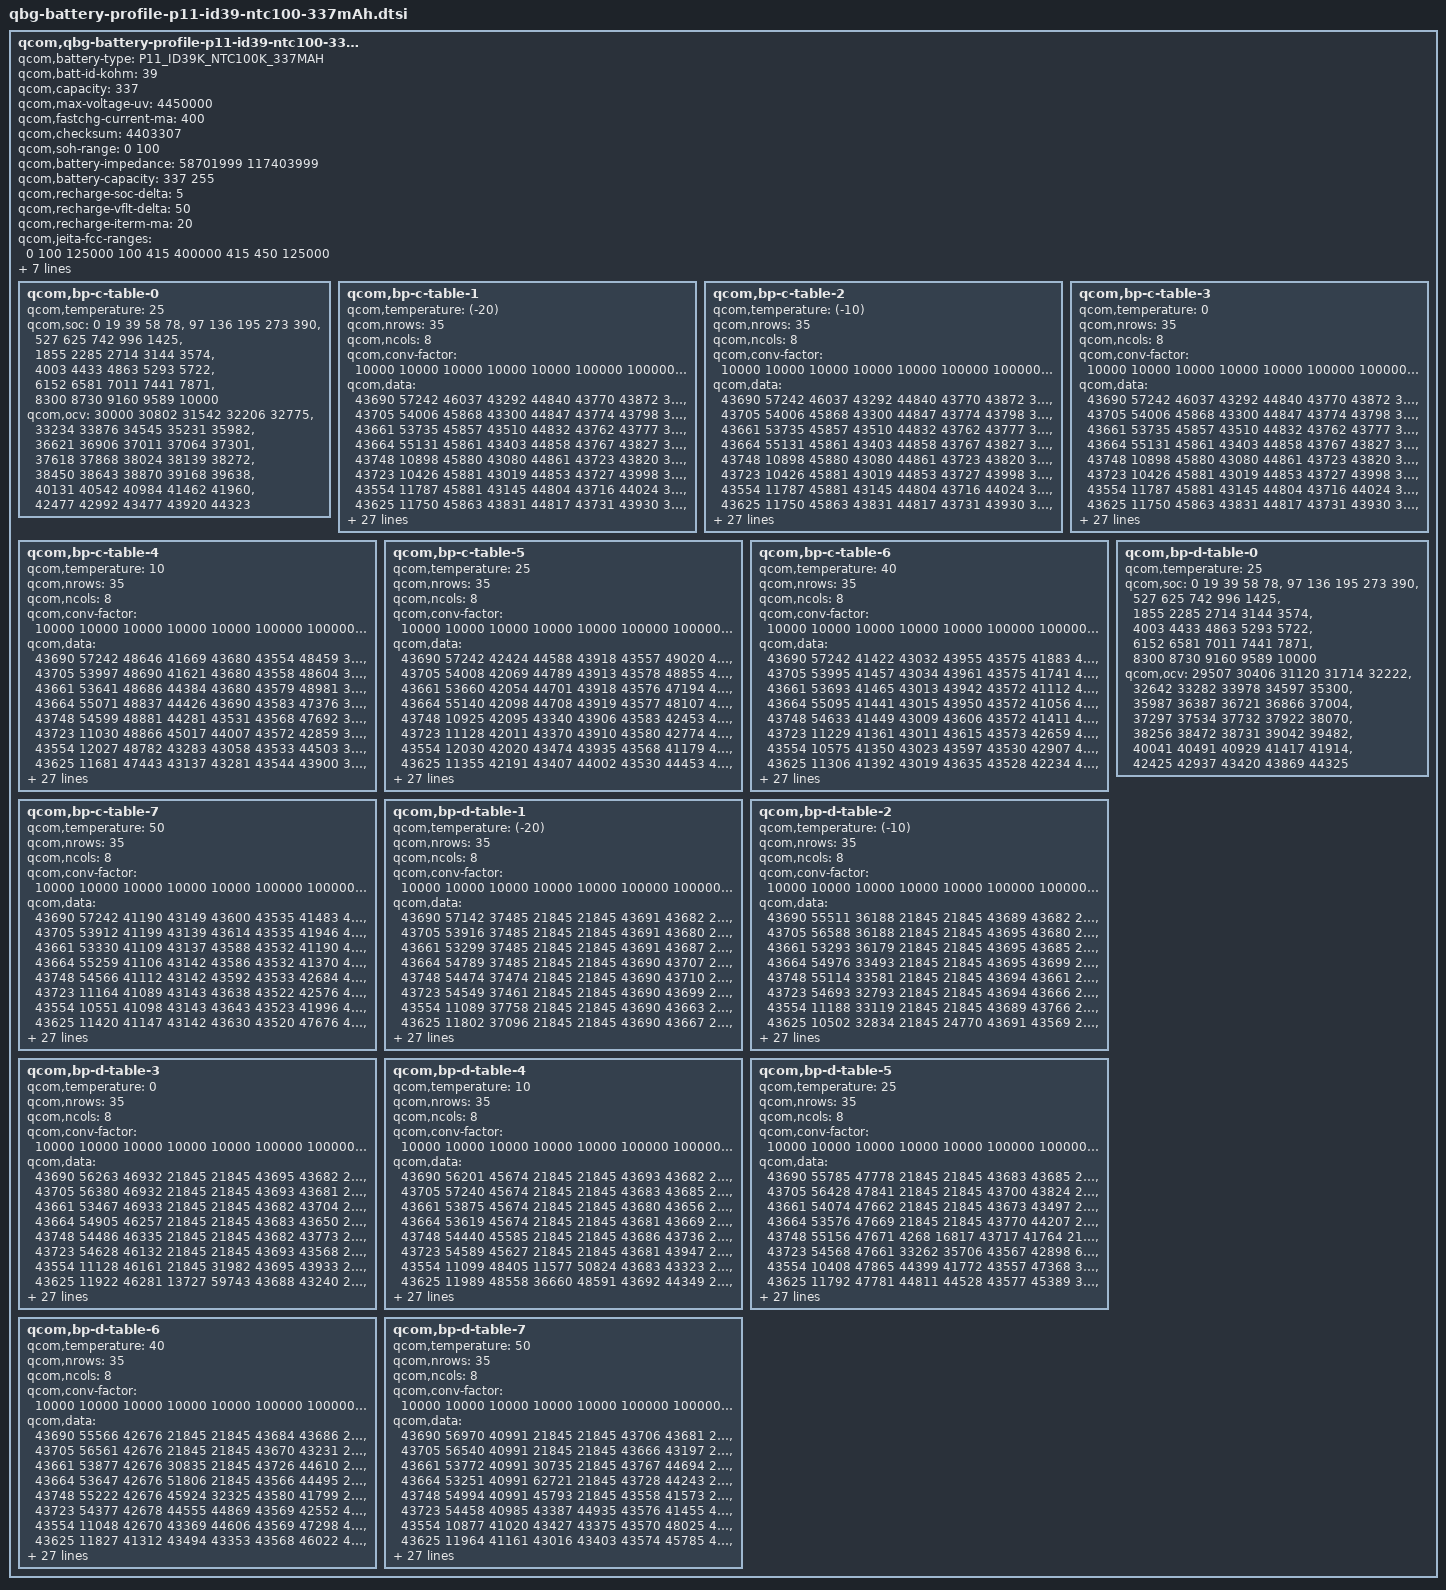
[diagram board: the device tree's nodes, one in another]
// SPDX-License-Identifier: GPL-2.0

/*QBG Profiling Rev. 2.7*/

qcom,qbg-battery-profile-p11-id39-ntc100-337mAh {
	qcom,battery-type = "P11_ID39K_NTC100K_337MAH";
	qcom,batt-id-kohm = <39>;
	qcom,capacity = <337>;
	qcom,max-voltage-uv = <4450000>;
	qcom,fastchg-current-ma = <400>;
	/*@5, 0.005V, 4% */
	qcom,checksum = <4403307>; /*@5, 0.005V, 4% */
	qcom,soh-range = <0 100>;
	/* Nominal_Impedance in 10nohm @ SOC 50% 25C* 0:fresh cell, 1: aged cell */
	qcom,battery-impedance = <58701999 117403999>;
	/* Nominal_Capacity in mAh. 0: fresh cell, 1:aged cell */
	/* 100% 80% */
	qcom,battery-capacity = <337 255>;
	/* SOC delta (in percent) dropped from EOC SOC to enable recharge */
	qcom,recharge-soc-delta =<5>;
	/* vfloat delta (in mV) dropped from regular vfloat in recharge */
	qcom,recharge-vflt-delta =<50>;
	/* termination current (in mA) in recharge */
	qcom,recharge-iterm-ma = <20>;

	/* LowTemp HighTemp CharingCurrent (uA) */
	qcom,jeita-fcc-ranges = <0  100 125000
				100 415 400000
				415 450 125000>;

	qcom,jeita-fv-ranges = <0   100 4450000
				100 415 4450000
				415 450 4450000>;

	/* COOL = 10 DegC, WARM = 41.5 DegC */
	qcom,jeita-soft-thresholds = <0x2b8a 0x1491>;
	/* COLD = 0 DegC, HOT = 45 DegC */
	qcom,jeita-hard-thresholds = <0x3257 0x128c>;
	/* COOL = 12 DegC, WARM = 39.5 DegC*/
	qcom,jeita-soft-hys-thresholds = <0x2a0b 0x15ca>;
	qcom,jeita-soft-fcc-ua = <125000 125000>;
	qcom,jeita-soft-fv-uv = <4450000 4450000>;

	qcom,bp-c-table-0 {
		qcom,temperature = <25>;
		qcom,soc = <    0    19    39    58    78>,
			<   97   136   195   273   390>,
			<  527   625   742   996  1425>,
			< 1855  2285  2714  3144  3574>,
			< 4003  4433  4863  5293  5722>,
			< 6152  6581  7011  7441  7871>,
			< 8300  8730  9160  9589 10000>;
		qcom,ocv = <30000 30802 31542 32206 32775>,
			<33234 33876 34545 35231 35982>,
			<36621 36906 37011 37064 37301>,
			<37618 37868 38024 38139 38272>,
			<38450 38643 38870 39168 39638>,
			<40131 40542 40984 41462 41960>,
			<42477 42992 43477 43920 44323>;
	};
	qcom,bp-c-table-1 {
		qcom,temperature = <(-20)>;
		qcom,nrows = <35>;
		qcom,ncols = <8>;
		qcom,conv-factor = <10000 10000 10000 10000 10000 100000 100000 10000>;
		qcom,data = <43690 57242 46037 43292 44840 43770 43872 39629>,
			<43705 54006 45868 43300 44847 43774 43798 34136>,
			<43661 53735 45857 43510 44832 43762 43777 34263>,
			<43664 55131 45861 43403 44858 43767 43827 34211>,
			<43748 10898 45880 43080 44861 43723 43820 33853>,
			<43723 10426 45881 43019 44853 43727 43998 33920>,
			<43554 11787 45881 43145 44804 43716 44024 34807>,
			<43625 11750 45863 43831 44817 43731 43930 34507>,
			<43963  8367 45982 43982 44803 43565 43904 33235>,
			<43820  9814 46011 43815 45006 43571 44005 32883>,
			<43173  9680 45632 43840 44669 43524 43830 32992>,
			<43227 14848 45682 43907 45024 43545 43932 33558>,
			<43084 15264 45685 43935 45017 43545 43909 33543>,
			<43342 15345 45646 43208 44758 43545 43845 33565>,
			<44859 14480 45662 41496 43228 43570 47692 34770>,
			<44437 14807 45641 41097 43453 43559 47566 33806>,
			<41543 16080 45617 41076 43481 43555 47505 33865>,
			<41008 16265 45760 41421 43278 43564 47877 33874>,
			<42722 16337 45604 41321 43347 43566 47710 34256>,
			<42844 16201 45794 41302 44777 43560 42430 34175>,
			<42249 15606 45811 42640 44551 43733 42174 39626>,
			<48123 15478 45799 42548 44943 43732 42381 39863>,
			<47189 15833 45720 42935 45004 43733 48768 39702>,
			<48647 13018 45697 42981 45036 43562 48413 39705>,
			<48368 12324 45792 42504 43266 43733 42519 34275>,
			<45730 12626 45643 42762 44798 43743 41214 39890>,
			<45855 14141 45640 42044 44606 43716 41552 39387>,
			<45513 13719 46012 42466 44981 43714 44485 40756>,
			<47035  2630 45867 42313 44186 43727 44887 37529>,
			<46101  2067 45936 47836 44326 43726 44969 37268>,
			<35526  3633 45070 47736 41735 43726 44721 38285>,
			<34992  3130 45181 47689 42924 43725 43492 60950>,
			<35170   546 45442 47817 47337 43719 43010 59125>,
			<36831   247 45328 42402 45363 43717 43188 62183>,
			<36282  1713 46795 41711 45227 43618 43921 65312>;
	};
	qcom,bp-c-table-2 {
		qcom,temperature = <(-10)>;
		qcom,nrows = <35>;
		qcom,ncols = <8>;
		qcom,conv-factor = <10000 10000 10000 10000 10000 100000 100000 10000>;
		qcom,data = <43690 57242 46037 43292 44840 43770 43872 39629>,
			<43705 54006 45868 43300 44847 43774 43798 34136>,
			<43661 53735 45857 43510 44832 43762 43777 34263>,
			<43664 55131 45861 43403 44858 43767 43827 34211>,
			<43748 10898 45880 43080 44861 43723 43820 33853>,
			<43723 10426 45881 43019 44853 43727 43998 33920>,
			<43554 11787 45881 43145 44804 43716 44024 34807>,
			<43625 11750 45863 43831 44817 43731 43930 34507>,
			<43963  8367 45982 43982 44803 43565 43904 33235>,
			<43820  9814 46011 43815 45006 43571 44005 32883>,
			<43173  9680 45632 43840 44669 43524 43830 32992>,
			<43227 14848 45682 43907 45024 43545 43932 33558>,
			<43084 15264 45685 43935 45017 43545 43909 33543>,
			<43342 15345 45646 43208 44758 43545 43845 33565>,
			<44859 14480 45662 41496 43228 43570 47692 34770>,
			<44437 14807 45641 41097 43453 43559 47566 33806>,
			<41543 16080 45617 41076 43481 43555 47505 33865>,
			<41008 16265 45760 41421 43278 43564 47877 33874>,
			<42722 16337 45604 41321 43347 43566 47710 34256>,
			<42844 16201 45794 41302 44777 43560 42430 34175>,
			<42249 15606 45811 42640 44551 43733 42174 39626>,
			<48123 15478 45799 42548 44943 43732 42381 39863>,
			<47189 15833 45720 42935 45004 43733 48768 39702>,
			<48647 13018 45697 42981 45036 43562 48413 39705>,
			<48368 12324 45792 42504 43266 43733 42519 34275>,
			<45730 12626 45643 42762 44798 43743 41214 39890>,
			<45855 14141 45640 42044 44606 43716 41552 39387>,
			<45513 13719 46012 42466 44981 43714 44485 40756>,
			<47035  2630 45867 42313 44186 43727 44887 37529>,
			<46101  2067 45936 47836 44326 43726 44969 37268>,
			<35526  3633 45070 47736 41735 43726 44721 38285>,
			<34992  3130 45181 47689 42924 43725 43492 60950>,
			<35170   546 45442 47817 47337 43719 43010 59125>,
			<36831   247 45328 42402 45363 43717 43188 62183>,
			<36282  1713 46795 41711 45227 43618 43921 65312>;
	};
	qcom,bp-c-table-3 {
		qcom,temperature = <0>;
		qcom,nrows = <35>;
		qcom,ncols = <8>;
		qcom,conv-factor = <10000 10000 10000 10000 10000 100000 100000 10000>;
		qcom,data = <43690 57242 46037 43292 44840 43770 43872 39629>,
			<43705 54006 45868 43300 44847 43774 43798 34136>,
			<43661 53735 45857 43510 44832 43762 43777 34263>,
			<43664 55131 45861 43403 44858 43767 43827 34211>,
			<43748 10898 45880 43080 44861 43723 43820 33853>,
			<43723 10426 45881 43019 44853 43727 43998 33920>,
			<43554 11787 45881 43145 44804 43716 44024 34807>,
			<43625 11750 45863 43831 44817 43731 43930 34507>,
			<43963  8367 45982 43982 44803 43565 43904 33235>,
			<43820  9814 46011 43815 45006 43571 44005 32883>,
			<43173  9680 45632 43840 44669 43524 43830 32992>,
			<43227 14848 45682 43907 45024 43545 43932 33558>,
			<43084 15264 45685 43935 45017 43545 43909 33543>,
			<43342 15345 45646 43208 44758 43545 43845 33565>,
			<44859 14480 45662 41496 43228 43570 47692 34770>,
			<44437 14807 45641 41097 43453 43559 47566 33806>,
			<41543 16080 45617 41076 43481 43555 47505 33865>,
			<41008 16265 45760 41421 43278 43564 47877 33874>,
			<42722 16337 45604 41321 43347 43566 47710 34256>,
			<42844 16201 45794 41302 44777 43560 42430 34175>,
			<42249 15606 45811 42640 44551 43733 42174 39626>,
			<48123 15478 45799 42548 44943 43732 42381 39863>,
			<47189 15833 45720 42935 45004 43733 48768 39702>,
			<48647 13018 45697 42981 45036 43562 48413 39705>,
			<48368 12324 45792 42504 43266 43733 42519 34275>,
			<45730 12626 45643 42762 44798 43743 41214 39890>,
			<45855 14141 45640 42044 44606 43716 41552 39387>,
			<45513 13719 46012 42466 44981 43714 44485 40756>,
			<47035  2630 45867 42313 44186 43727 44887 37529>,
			<46101  2067 45936 47836 44326 43726 44969 37268>,
			<35526  3633 45070 47736 41735 43726 44721 38285>,
			<34992  3130 45181 47689 42924 43725 43492 60950>,
			<35170   546 45442 47817 47337 43719 43010 59125>,
			<36831   247 45328 42402 45363 43717 43188 62183>,
			<36282  1713 46795 41711 45227 43618 43921 65312>;
	};
	qcom,bp-c-table-4 {
		qcom,temperature = <10>;
		qcom,nrows = <35>;
		qcom,ncols = <8>;
		qcom,conv-factor = <10000 10000 10000 10000 10000 100000 100000 10000>;
		qcom,data = <43690 57242 48646 41669 43680 43554 48459 35142>,
			<43705 53997 48690 41621 43680 43558 48604 35113>,
			<43661 53641 48686 44384 43680 43579 48981 35263>,
			<43664 55071 48837 44426 43690 43583 47376 34830>,
			<43748 54599 48881 44281 43531 43568 47692 34969>,
			<43723 11030 48866 45017 44007 43572 42859 35694>,
			<43554 12027 48782 43283 43058 43533 44503 35420>,
			<43625 11681 47443 43137 43281 43544 43900 35493>,
			<43963  9071 47486 43167 43318 43543 43890 46557>,
			<43820  9749 47434 43236 43508 43618 43198 46146>,
			<43173  9707 47398 43121 43010 43625 43416 46284>,
			<43227 15043 47557 43403 43164 43542 44691 46935>,
			<43084 14951 47569 43285 43838 43540 41654 46926>,
			<43342 15266 47556 44745 43983 43624 42071 46261>,
			<44859 15197 47564 44042 43253 43580 42223 35401>,
			<44437 14740 47517 44533 43439 43559 42407 35591>,
			<41543 16023 47524 44415 43405 43555 42317 35695>,
			<41008 15997 47231 41628 43394 43565 48041 35691>,
			<42722 16281 47108 41671 43492 43565 47708 35705>,
			<42844 16140 47160 41504 43483 43565 42123 35663>,
			<42249 15508 47137 41703 44716 43566 41773 34958>,
			<48123 15439 47312 41628 44572 43563 41579 34861>,
			<47189 15671 47345 41671 44976 43732 41167 35248>,
			<48647 12863 47328 41919 44609 43562 47207 35218>,
			<48368 12422 47341 41963 43341 43561 48247 35038>,
			<45730 14023 47249 41619 43455 43562 44395 35544>,
			<45855 14173 47256 41892 43074 43734 41097 35765>,
			<45513 13620 47239 41971 43449 43730 41533 35599>,
			<47035  3017 47339 41119 43264 43717 44107 35302>,
			<46101  2537 47145 41390 44547 43713 44833 36637>,
			<35526  3997 47174 41422 44213 43718 44763 33489>,
			<34992  3475 47604 41256 41672 43717 43321 34470>,
			<35170   903 47480 41431 41336 43741 43448 39850>,
			<36831    91 48893 41010 47271 43562 43052 37462>,
			<36282  1547 48903 44635 48541 43924 43911 37362>;
	};
	qcom,bp-c-table-5 {
		qcom,temperature = <25>;
		qcom,nrows = <35>;
		qcom,ncols = <8>;
		qcom,conv-factor = <10000 10000 10000 10000 10000 100000 100000 10000>;
		qcom,data = <43690 57242 42424 44588 43918 43557 49020 48210>,
			<43705 54008 42069 44789 43913 43578 48855 48148>,
			<43661 53660 42054 44701 43918 43576 47194 48170>,
			<43664 55140 42098 44708 43919 43577 48107 48362>,
			<43748 10925 42095 43340 43906 43583 42453 48981>,
			<43723 11128 42011 43370 43910 43580 42774 48917>,
			<43554 12030 42020 43474 43935 43568 41179 49123>,
			<43625 11355 42191 43407 44002 43530 44453 48739>,
			<43963  9013 42210 43080 43994 43520 44993 48848>,
			<43820  9764 42142 43129 43822 43547 44985 48877>,
			<43173  9639 42123 43053 43791 43541 44573 47447>,
			<43227 14976 42167 43214 43835 43626 44839 47412>,
			<43084 14905 42155 43012 43915 43544 41955 47563>,
			<43342 14946 42844 43129 43820 43550 41494 47434>,
			<44859 15135 42774 43329 43226 43528 44356 48952>,
			<44437 14424 42787 44694 43083 43531 41574 48317>,
			<41543 14662 42952 44767 43115 43572 41230 48980>,
			<41008 15906 42986 44600 43041 43571 42938 49000>,
			<42722 15953 42889 44653 43223 43581 42609 49000>,
			<42844 16170 42915 44969 43068 43571 41372 48312>,
			<42249 15512 42563 44792 43280 43569 44963 48365>,
			<48123 15449 42597 43337 44573 43579 44745 48155>,
			<47189 15740 42523 44702 44570 43558 44195 48193>,
			<48647 13226 42505 44620 44720 43577 42650 48225>,
			<48368 12412 42554 44649 43115 43577 41013 49094>,
			<45730 13929 42710 44585 43238 43556 44067 48700>,
			<45855 13556 42719 44595 43216 43552 45017 48764>,
			<45513  2738 42716 44631 43037 43564 44619 48934>,
			<47035  2908 42712 45051 43455 43560 44769 48353>,
			<46101  2370 42538 44203 43414 43562 44559 48531>,
			<35526  3911 42509 44131 44690 43728 43343 46060>,
			<34992  3418 42566 44515 44862 43732 43326 45525>,
			<35170   895 42989 44437 44315 43552 43500 46259>,
			<36831   314 42856 44067 42671 43577 43063 34960>,
			<36282  1929 42003 44694 42603 43556 43840 35662>;
	};
	qcom,bp-c-table-6 {
		qcom,temperature = <40>;
		qcom,nrows = <35>;
		qcom,ncols = <8>;
		qcom,conv-factor = <10000 10000 10000 10000 10000 100000 100000 10000>;
		qcom,data = <43690 57242 41422 43032 43955 43575 41883 47854>,
			<43705 53995 41457 43034 43961 43575 41741 47748>,
			<43661 53693 41465 43013 43942 43572 41112 47795>,
			<43664 55095 41441 43015 43950 43572 41056 47785>,
			<43748 54633 41449 43009 43606 43572 41411 42308>,
			<43723 11229 41361 43011 43615 43573 42659 42352>,
			<43554 10575 41350 43023 43597 43530 42907 42271>,
			<43625 11306 41392 43019 43635 43528 42234 42275>,
			<43963  9093 41388 43061 43643 43534 42101 42444>,
			<43820  9864 41055 43045 43623 43521 42012 42394>,
			<43173  9230 41033 43219 43634 43551 42931 42402>,
			<43227  9599 41078 43187 43584 43628 41015 41999>,
			<43084 15097 41086 43880 43585 43616 41094 42221>,
			<43342 14882 41056 43841 43975 43631 44248 42078>,
			<44859 15311 40986 43204 43242 43548 44930 47850>,
			<44437 14391 41009 43009 43231 43545 44261 47631>,
			<41543 14627 40992 43133 43236 43545 41403 47679>,
			<41008 16021 41171 43036 43183 43525 40970 47754>,
			<42722 15999 41167 43026 43855 43529 41580 42321>,
			<42844 16321 41191 43453 43847 43573 41661 47810>,
			<42249 15541 41118 43398 43049 43527 45019 47693>,
			<48123 15443 41140 43861 44730 43551 43074 48001>,
			<47189 15681 41126 43242 44721 43535 44761 48076>,
			<48647 13190 41812 43116 43461 43528 41903 48049>,
			<48368 12711 41822 43010 43183 43528 44390 42254>,
			<45730 13938 41798 43061 43805 43530 44219 42472>,
			<45855 13527 41806 43116 43898 43569 44955 42285>,
			<45513  2795 41846 43426 43139 43582 44741 47745>,
			<47035  2188 41842 43514 43053 43556 43351 47690>,
			<46101  3767 41841 43384 43025 43554 44777 47885>,
			<35526  3213 41800 44681 43450 43565 44707 47306>,
			<34992   655 41808 44973 43282 43559 44786 48808>,
			<35170   853 41096 44966 44630 43574 44709 48952>,
			<36831   287 41155 44581 44413 43522 43410 48453>,
			<36282  2034 41368 43043 41695 43531 43846 48578>;
	};
	qcom,bp-c-table-7 {
		qcom,temperature = <50>;
		qcom,nrows = <35>;
		qcom,ncols = <8>;
		qcom,conv-factor = <10000 10000 10000 10000 10000 100000 100000 10000>;
		qcom,data = <43690 57242 41190 43149 43600 43535 41483 42191>,
			<43705 53912 41199 43139 43614 43535 41946 42226>,
			<43661 53330 41109 43137 43588 43532 41190 42209>,
			<43664 55259 41106 43142 43586 43532 41370 42132>,
			<43748 54566 41112 43142 43592 43533 42684 42136>,
			<43723 11164 41089 43143 43638 43522 42576 42127>,
			<43554 10551 41098 43143 43643 43523 41996 42151>,
			<43625 11420 41147 43142 43630 43520 47676 42820>,
			<43963  8776 41129 43136 43538 43521 47350 42848>,
			<43820  8569 41822 43148 43527 43524 47425 42763>,
			<43173  9464 41795 43191 43524 43549 47538 42795>,
			<43227  9530 41801 43885 43624 43621 42162 42895>,
			<43084 15025 41844 44031 43645 43595 41734 42602>,
			<43342 15078 41840 43837 43924 43643 44281 42971>,
			<44859 15246 41826 43860 43853 43628 44980 42196>,
			<44437 14581 41751 43136 43170 43629 44166 42095>,
			<41543 14823 41752 43192 43160 43629 44501 42092>,
			<41008 16063 41743 43866 43855 43631 41639 42208>,
			<42722 15892 41790 43182 43813 43538 41705 42172>,
			<42844 16373 41769 43214 43834 43521 44368 42200>,
			<42249 15536 41946 43046 43170 43546 45004 42408>,
			<48123 15442 41973 43889 43420 43617 43490 42486>,
			<47189 15699 41957 43810 43284 43627 43383 42454>,
			<48647 13292 41960 43870 43451 43538 44400 42377>,
			<48368 12684 41875 43864 43785 43539 44295 42768>,
			<45730 13901 41882 43847 43973 43548 44183 42966>,
			<45855 13368 41869 43183 43827 43524 44647 42774>,
			<45513  2800 41908 43237 43892 43532 44590 42237>,
			<47035  2282 41906 43032 43193 43575 44574 42064>,
			<46101  3735 41916 43099 43209 43581 44786 42300>,
			<35526  3307 41904 43507 43066 43576 44644 47763>,
			<34992   747 41868 43268 43514 43556 44716 48076>,
			<35170   191 41879 43361 44777 43528 43334 47137>,
			<36831   355 41944 43297 44258 43548 43509 48867>,
			<36282  2010 41139 43255 44119 43526 43253 48686>;
	};
	qcom,bp-d-table-0 {
		qcom,temperature = <25>;
		qcom,soc = <    0    19    39    58    78>,
			<   97   136   195   273   390>,
			<  527   625   742   996  1425>,
			< 1855  2285  2714  3144  3574>,
			< 4003  4433  4863  5293  5722>,
			< 6152  6581  7011  7441  7871>,
			< 8300  8730  9160  9589 10000>;
		qcom,ocv = <29507 30406 31120 31714 32222>,
			<32642 33282 33978 34597 35300>,
			<35987 36387 36721 36866 37004>,
			<37297 37534 37732 37922 38070>,
			<38256 38472 38731 39042 39482>,
			<40041 40491 40929 41417 41914>,
			<42425 42937 43420 43869 44325>;
	};
	qcom,bp-d-table-1 {
		qcom,temperature = <(-20)>;
		qcom,nrows = <35>;
		qcom,ncols = <8>;
		qcom,conv-factor = <10000 10000 10000 10000 10000 100000 100000 10000>;
		qcom,data = <43690 57142 37485 21845 21845 43691 43682 21845>,
			<43705 53916 37485 21845 21845 43691 43680 21845>,
			<43661 53299 37485 21845 21845 43691 43687 21845>,
			<43664 54789 37485 21845 21845 43690 43707 21845>,
			<43748 54474 37474 21845 21845 43690 43710 21845>,
			<43723 54549 37461 21845 21845 43690 43699 21845>,
			<43554 11089 37758 21845 21845 43690 43663 21845>,
			<43625 11802 37096 21845 21845 43690 43667 21845>,
			<43963 11568 37085 21845 24628 43690 43771 21845>,
			<43820  8295 37100 21845 51444 43690 43552 21845>,
			<43173 10136 37522 21845 36950 43690 43610 21845>,
			<43227  9366 40022 21845 33860 43690 44014 21845>,
			<43084  9299 40829 21845 36759 43690 43812 21845>,
			<43342  9542 40588  3413 46058 43691 43136 21845>,
			<44859 14912 39205 11349 34828 43691 43242 21845>,
			<44437 15154 39797 52142 47076 43688 43218 21845>,
			<41543 14477 34092 57986 48569 43688 43030 22029>,
			<41008 14366 34642 40284 47289 43689 43436 31886>,
			<42722 14819 34333 34571 42077 43694 43502  5759>,
			<42844 14656 34535 35864 42927 43694 43477   294>,
			<42249 15934 33051 35675 41252 43695 43294 13335>,
			<48123 16365 33217 47093 41083 43692 43317 14738>,
			<47189 15520 33213 45253 41855 43693 43368  9177>,
			<48647 15477 32898 45757 41551 43693 44730 10779>,
			<48368 15717 33752 48161 44310 43683 44620 53886>,
			<45730 12895 33722 48259 44040 43680 44449 55667>,
			<45855 12509 33311 48371 44184 43680 41090 56175>,
			<45513 14016 33329 48264 44471 43681 41300 56195>,
			<47035 13630 33312 48491 41762 43687 45247 56916>,
			<46101  2856 33296 48535 41347 43687 47956 56462>,
			<35526  2434 33522 48212 41369 43684 41226 57207>,
			<34992  3990 33531 48193 41036 43662 41280 56546>,
			<35170  3355 33490 48584 41160 43666 42614 56415>,
			<36831   156 36116 46021 41918 43690 44456 56450>,
			<36282  2045 35902 45375 41614 43690 43690 57019>;
	};
	qcom,bp-d-table-2 {
		qcom,temperature = <(-10)>;
		qcom,nrows = <35>;
		qcom,ncols = <8>;
		qcom,conv-factor = <10000 10000 10000 10000 10000 100000 100000 10000>;
		qcom,data = <43690 55511 36188 21845 21845 43689 43682 21845>,
			<43705 56588 36188 21845 21845 43695 43680 21845>,
			<43661 53293 36179 21845 21845 43695 43685 21845>,
			<43664 54976 33493 21845 21845 43695 43699 21845>,
			<43748 55114 33581 21845 21845 43694 43661 21845>,
			<43723 54693 32793 21845 21845 43694 43666 21845>,
			<43554 11188 33119 21845 21845 43689 43766 21845>,
			<43625 10502 32834 21845 24770 43691 43569 21845>,
			<43963 11323 32959 21845 58821 43690 43605 21845>,
			<43820  8382 33395 18832 46155 43690 43782 21845>,
			<43173 10169 36346 54036 48036 43691 43071 21845>,
			<43227  9261 36094 64346 42832 43691 43502 21845>,
			<43084  9684 36000 37038 41281 43691 44717 19319>,
			<43342 15085 36513 46413 44388 43689 45027  2623>,
			<44859 15244 35065 35590 41445 43694 43349 15458>,
			<44437 15213 35826 45828 41944 43692 44675 55006>,
			<41543 14586 35581 48673 44517 43683 44560 49348>,
			<41008 14463 46435 48013 44825 43686 44823 62535>,
			<42722 14837 46397 42099 44622 43707 44245 62204>,
			<42844 14683 46375 42995 44750 43697 44439 65228>,
			<42249 15905 46513 41232 43386 43747 41693 64414>,
			<48123 16275 46584 41362 43471 43716 41887 58482>,
			<47189 15542 46497 41363 43486 43743 41154 59146>,
			<48647 15828 46171 41314 43372 43562 47558 59233>,
			<48368 13232 46527 42726 44740 43554 48218 58573>,
			<45730 12317 46572 42532 44947 43558 48731 58458>,
			<45855 13837 46507 42905 44187 43576 48179 58746>,
			<45513 13727 46203 42767 41563 43559 47258 63707>,
			<47035  2613 46169 42136 41607 43553 42655 64278>,
			<46101  2168 46112 42347 41626 43564 42293 63563>,
			<35526  3654 46129 47677 41535 43728 42376 65050>,
			<34992  3188 46092 48002 41598 43738 42891 64670>,
			<35170   621 46123 48090 41522 43714 41462 64628>,
			<36831    96 46269 48089 44242 43773 41585 64594>,
			<36282  2045 46970 48067 44628 43758 44221 64568>;
	};
	qcom,bp-d-table-3 {
		qcom,temperature = <0>;
		qcom,nrows = <35>;
		qcom,ncols = <8>;
		qcom,conv-factor = <10000 10000 10000 10000 10000 100000 100000 10000>;
		qcom,data = <43690 56263 46932 21845 21845 43695 43682 21845>,
			<43705 56380 46932 21845 21845 43693 43681 21845>,
			<43661 53467 46933 21845 21845 43682 43704 21845>,
			<43664 54905 46257 21845 21845 43683 43650 21845>,
			<43748 54486 46335 21845 21845 43682 43773 21845>,
			<43723 54628 46132 21845 21845 43693 43568 21845>,
			<43554 11128 46161 21845 31982 43695 43933 21845>,
			<43625 11922 46281 13727 59743 43688 43240 21845>,
			<43963 11386 46850 62968 45528 43691 43306 21845>,
			<43820  8367 47039 39248 41328 43691 44740 31723>,
			<43173  9809 46726 45395 44063 43688 44997 15510>,
			<43227  9252 45380 48918 44915 43689 44138 11013>,
			<43084  9505 45446 47640 44630 43695 44125 50294>,
			<43342 14988 45273 41427 43504 43682 41659 64673>,
			<44859 14967 46052 42922 43505 43687 41701 63707>,
			<44437 15180 45650 41233 43296 43708 42841 59133>,
			<41543 14449 45617 41104 43378 43745 47714 57933>,
			<41008 14799 45800 41861 43374 43737 42316 61335>,
			<42722 14614 45700 41474 43505 43741 41230 60320>,
			<42844 16010 45711 41616 43078 43733 41148 38699>,
			<42249 15873 45723 41658 43068 43561 41214 36935>,
			<48123 16232 45808 41577 43031 43558 45202 36879>,
			<47189 15433 45818 41582 43504 43557 48588 37089>,
			<48647 12980 45803 41593 44711 43576 47251 37103>,
			<48368 13091 45699 41871 44598 43577 42472 36898>,
			<45730 12791 45698 41811 45016 43582 42377 37176>,
			<45855 14093 45822 41389 44434 43580 47338 38854>,
			<45513 13763 48458 41358 41724 43562 41879 38060>,
			<47035  3030 48403 42907 44312 43566 42707 38296>,
			<46101  2535 48457 42967 41614 43739 41942 60034>,
			<35526  3987 48403 42171 41726 43727 41718 60365>,
			<34992  3479 48592 42403 41724 43723 41514 59778>,
			<35170   899 48576 42328 41658 43761 41583 61021>,
			<36831   421 48417 47642 44221 43750 41517 60641>,
			<36282  2018 48483 48020 44650 43671 44310 60863>;
	};
	qcom,bp-d-table-4 {
		qcom,temperature = <10>;
		qcom,nrows = <35>;
		qcom,ncols = <8>;
		qcom,conv-factor = <10000 10000 10000 10000 10000 100000 100000 10000>;
		qcom,data = <43690 56201 45674 21845 21845 43693 43682 21845>,
			<43705 57240 45674 21845 21845 43683 43685 21845>,
			<43661 53875 45674 21845 21845 43680 43656 21845>,
			<43664 53619 45674 21845 21845 43681 43669 21845>,
			<43748 54440 45585 21845 21845 43686 43736 21845>,
			<43723 54589 45627 21845 21845 43681 43947 21845>,
			<43554 11099 48405 11577 50824 43683 43323 21845>,
			<43625 11989 48558 36660 48591 43692 44349  2538>,
			<43963 11681 48253 45485 41317 43695 41460 12062>,
			<43820  9055 48274 47957 44847 43695 41317 50008>,
			<43173  9832 48996 41043 43491 43683 41046 63714>,
			<43227  9463 49113 41983 43405 43684 41366 57382>,
			<43084  9693 49121 41575 43420 43705 41104 60818>,
			<43342 15017 49150 44281 43230 43664 41800 37950>,
			<44859 14878 48891 44405 43010 43651 41748 60360>,
			<44437 15221 48806 44100 43304 43773 41128 38411>,
			<41543 14435 48810 44034 43292 43562 41209 40220>,
			<41008 14845 47484 44243 43481 43558 40972 38971>,
			<42722 14610 47401 44177 43120 43579 41158 33936>,
			<42844 16023 47557 44267 43201 43577 42234 33124>,
			<42249 16367 47572 44070 43089 43571 45593 33087>,
			<48123 15544 47407 44270 43509 43580 47839 32869>,
			<47189 15783 47558 44283 43295 43568 42534 32998>,
			<48647 13027 47601 44038 44728 43575 41434 32996>,
			<48368 13155 47608 44540 44582 43569 41028 32799>,
			<45730 12551 47594 41697 44996 43580 41359 33098>,
			<45855 14173 47499 41786 44143 43582 42885 34676>,
			<45513 13675 47540 41164 44458 43579 41827 33854>,
			<47035  2852 47522 41172 44318 43742 44047 34250>,
			<46101  2517 47493 41424 44519 43737 44111 39656>,
			<35526  4055 47521 42691 44096 43738 44524 39868>,
			<34992  3540 47177 42596 44109 43715 44515 39752>,
			<35170   975 47220 42580 44128 43723 44516 39068>,
			<36831   413 47182 42880 44978 43773 41616 39807>,
			<36282  1950 47197 42988 43371 43750 41918 39624>;
	};
	qcom,bp-d-table-5 {
		qcom,temperature = <25>;
		qcom,nrows = <35>;
		qcom,ncols = <8>;
		qcom,conv-factor = <10000 10000 10000 10000 10000 100000 100000 10000>;
		qcom,data = <43690 55785 47778 21845 21845 43683 43685 21845>,
			<43705 56428 47841 21845 21845 43700 43824 21845>,
			<43661 54074 47662 21845 21845 43673 43497 21845>,
			<43664 53576 47669 21845 21845 43770 44207 21845>,
			<43748 55156 47671  4268 16817 43717 41764 21845>,
			<43723 54568 47661 33262 35706 43567 42898 65021>,
			<43554 10408 47865 44399 41772 43557 47368 32895>,
			<43625 11792 47781 44811 44528 43577 45389 36459>,
			<43963 11663 42311 44962 44934 43580 46175 35725>,
			<43820  9038 42261 44570 43435 43568 46158 46243>,
			<43173  9785 42248 44748 43843 43573 45937 46778>,
			<43227  9353 42462 44675 43778 43528 47973 45178>,
			<43084  9691 42446 44749 43864 43534 42617 45138>,
			<43342 15016 42487 44683 43813 43530 42684 45879>,
			<44859 14886 42390 44728 43776 43577 41414 45942>,
			<44437 15131 42085 44714 43236 43532 41857 45618>,
			<41543 14388 42204 44712 43067 43526 41930 48393>,
			<41008 14798 42139 44715 43134 43547 41442 48609>,
			<42722 16008 42175 44727 43405 43540 42808 48637>,
			<42844 15900 42824 43316 43463 43544 41719 48145>,
			<42249 16346 42752 43368 43455 43536 41721 48285>,
			<48123 15586 42964 43376 43033 43538 41664 48896>,
			<47189 15841 42994 43352 43212 43545 41900 49049>,
			<48647 12840 42902 44710 43209 43521 41735 49038>,
			<48368 12432 42889 44576 43029 43544 42015 49009>,
			<45730 14019 42924 45052 43374 43628 48490 48393>,
			<45855 13441 42587 44614 44593 43531 41096 48470>,
			<45513 13643 42572 44548 44566 43580 44276 48501>,
			<47035  2915 42566 44975 44744 43572 44878 48464>,
			<46101  2320 42581 44860 43277 43529 44257 48477>,
			<35526  3859 42917 44164 43104 43530 44356 48474>,
			<34992  3347 42880 44266 43070 43581 41531 48448>,
			<35170   822 43003 44912 43018 43579 41667 48499>,
			<36831   503 42949 44947 43018 43576 41666 48583>,
			<36282  1935 42962 44591 43059 43581 41685 48561>;
	};
	qcom,bp-d-table-6 {
		qcom,temperature = <40>;
		qcom,nrows = <35>;
		qcom,ncols = <8>;
		qcom,conv-factor = <10000 10000 10000 10000 10000 100000 100000 10000>;
		qcom,data = <43690 55566 42676 21845 21845 43684 43686 21845>,
			<43705 56561 42676 21845 21845 43670 43231 21845>,
			<43661 53877 42676 30835 21845 43726 44610 21845>,
			<43664 53647 42676 51806 21845 43566 44495 21845>,
			<43748 55222 42676 45924 32325 43580 41799 22309>,
			<43723 54377 42678 44555 44869 43569 42552 45787>,
			<43554 11048 42670 43369 44606 43569 47298 48917>,
			<43625 11827 41312 43494 43353 43568 46022 48871>,
			<43963 11717 41249 43400 43329 43581 46192 47435>,
			<43820  8375 41411 43449 43019 43573 35655 47340>,
			<43173  9791 41440 43091 43986 43531 46394 47717>,
			<43227  9403 41367 43098 43907 43573 48376 47822>,
			<43084  9719 41362 43501 44004 43572 42729 47689>,
			<43342  9548 41357 43449 43951 43570 42694 47864>,
			<44859 15089 41378 43019 43954 43532 41328 42343>,
			<44437 15312 41082 43116 43827 43543 41795 47757>,
			<41543 14534 40961 43036 43854 43631 41735 47769>,
			<41008 14820 41016 43033 43250 43634 41090 47831>,
			<42722 16012 41171 43031 43122 43607 41572 47711>,
			<42844 15982 41204 43441 43238 43915 41789 47642>,
			<42249 16172 41198 43399 43174 43588 41032 47818>,
			<48123 15562 41092 43427 43886 43592 41350 42315>,
			<47189 15857 41138 43118 43814 43620 40991 42476>,
			<48647 12838 41132 43062 43832 43537 40964 42383>,
			<48368 12521 41823 43033 43164 43536 42539 42342>,
			<45730 14067 41805 43087 43326 43542 42160 48017>,
			<45855 14167 41845 43220 44712 43533 44229 48120>,
			<45513 13678 41841 43058 43391 43520 45047 48109>,
			<47035  2866 41846 43471 43009 43646 44062 48040>,
			<46101  2344 41800 44725 43999 43619 41468 47623>,
			<35526  4053 41798 43333 44025 43535 41006 47867>,
			<34992  3370 41809 43318 44008 43570 41451 47791>,
			<35170   973 41121 43464 43904 43568 42764 42347>,
			<36831   388 41149 43126 43970 43528 41082 42436>,
			<36282  1625 41098 43234 43853 43520 43935 42431>;
	};
	qcom,bp-d-table-7 {
		qcom,temperature = <50>;
		qcom,nrows = <35>;
		qcom,ncols = <8>;
		qcom,conv-factor = <10000 10000 10000 10000 10000 100000 100000 10000>;
		qcom,data = <43690 56970 40991 21845 21845 43706 43681 21845>,
			<43705 56540 40991 21845 21845 43666 43197 21845>,
			<43661 53772 40991 30735 21845 43767 44694 21845>,
			<43664 53251 40991 62721 21845 43728 44243 21845>,
			<43748 54994 40991 45793 21845 43558 41573 21845>,
			<43723 54458 40985 43387 44935 43576 41455 49062>,
			<43554 10877 41020 43427 43375 43570 48025 47144>,
			<43625 11964 41161 43016 43403 43574 45785 48099>,
			<43963 11663 41186 43067 43366 43574 46808 47889>,
			<43820  9034 41088 43225 43067 43528 35542 47774>,
			<43173  9981 41145 43203 43996 43533 35622 42063>,
			<43227 10107 41132 43206 43949 43533 46883 42202>,
			<43084  9612 41130 43028 43943 43572 42320 42095>,
			<43342  9492 41823 43008 43625 43575 47626 42230>,
			<44859 14976 41846 43189 43639 43548 42097 42768>,
			<44437 15341 41749 43261 44010 43618 41440 42137>,
			<41543 14486 41731 43237 43968 43640 42658 42133>,
			<41008 14735 41789 43243 43877 43602 41396 42180>,
			<42722 16061 41773 43014 43146 44018 41006 42368>,
			<42844 15985 41945 43114 43241 43938 41169 42467>,
			<42249 16189 41931 43022 43856 43605 41832 42099>,
			<48123 15552 41957 43056 43997 43611 41356 42134>,
			<47189 15822 41876 43201 43917 43646 42778 42812>,
			<48647 12849 41860 43138 43923 43618 42777 42960>,
			<48368 12512 41866 43198 43194 43631 42682 42148>,
			<45730 14052 41918 43195 43510 43624 41750 42492>,
			<45855 14161 41894 43840 43275 43624 44203 42449>,
			<45513 13586 41901 43262 43439 43642 44911 42494>,
			<47035  2862 41901 43314 44010 43601 42812 42076>,
			<46101  2521 41891 43482 43963 43625 42705 42038>,
			<35526  4056 41895 43441 43614 43575 42898 42141>,
			<34992  3546 41912 43029 43586 43568 42844 42853>,
			<35170  1016 41905 43208 43589 43535 42813 42964>,
			<36831   432 41859 43198 43965 43537 41253 42982>,
			<36282  1653 41885 43890 43922 43641 41831 42984>;
	};
};
